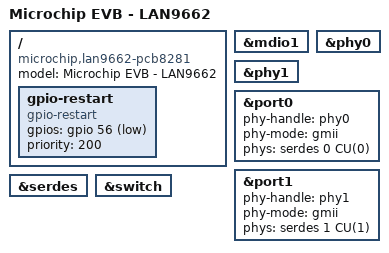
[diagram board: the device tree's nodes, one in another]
// SPDX-License-Identifier: (GPL-2.0+ OR MIT)
/*
 * lan966x_pcb8281.dts - Device Tree file for PCB8281
 */
/dts-v1/;

#include "lan966x.dtsi"
#include "dt-bindings/phy/phy-lan966x-serdes.h"

/ {
	model = "Microchip EVB - LAN9662";
	compatible = "microchip,lan9662-pcb8281", "microchip,lan9662", "microchip,lan966";

	gpio-restart {
		compatible = "gpio-restart";
		gpios = <&gpio 56 GPIO_ACTIVE_LOW>;
		priority = <200>;
	};
};

&mdio1 {
	status = "okay";
};

&phy0 {
	status = "okay";
};

&phy1 {
	status = "okay";
};

&port0 {
	phy-handle = <&phy0>;
	phy-mode = "gmii";
	phys = <&serdes 0 CU(0)>;
	status = "okay";
};

&port1 {
	phy-handle = <&phy1>;
	phy-mode = "gmii";
	phys = <&serdes 1 CU(1)>;
	status = "okay";
};

&serdes {
	status = "okay";
};

&switch {
	status = "okay";
};
